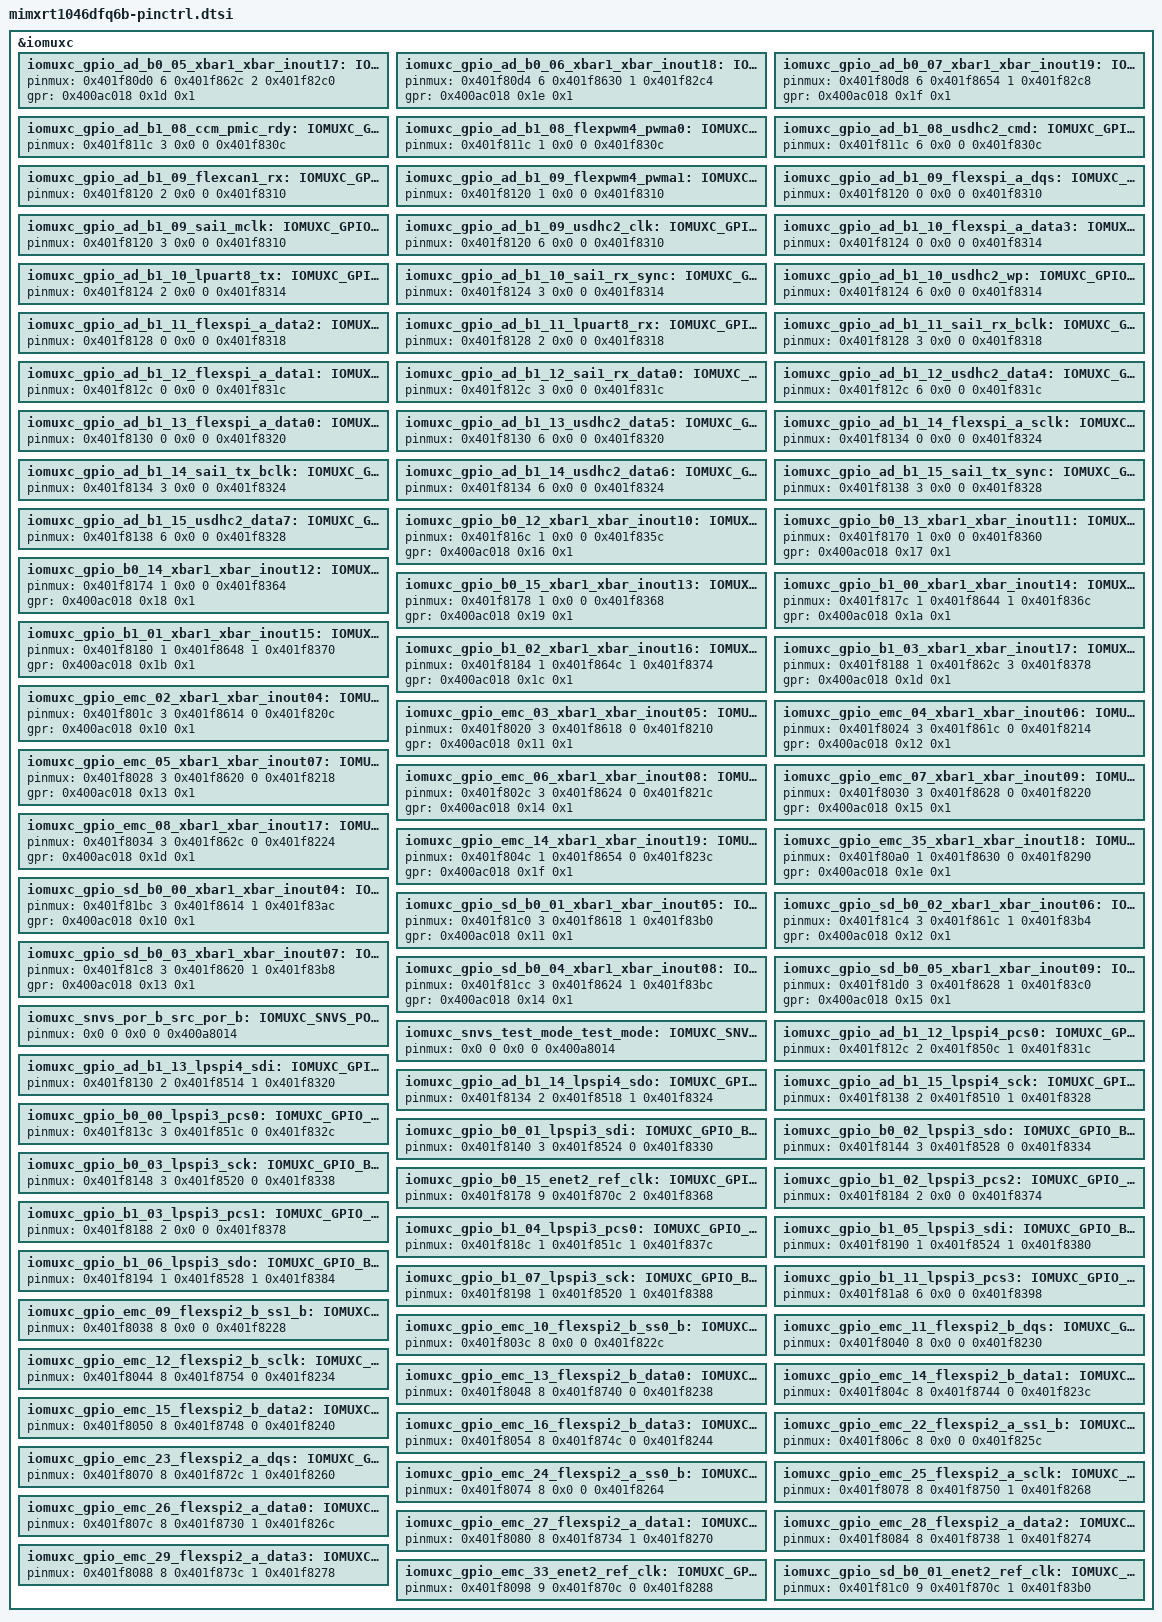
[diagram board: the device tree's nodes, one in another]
/*
 * Copyright 2026, NXP
 * SPDX-License-Identifier: Apache-2.0
 *
 * Note: File generated by gen_soc_headers.py
 * from configuration data for MIMXRT1046DFQ6B
 */

/*
 * Delta-deduplicated by dedup_pinctrl.py:
 * based on mimxrt1064dvj6a-pinctrl.dtsi with this part's differences applied
 * below (223 removed, 53 changed,
 * 34 added). Regenerate with dedup_pinctrl.py;
 * do not edit by hand.
 * target-hash: 304d2df1a5f7ddd6
 */

#include "mimxrt1064dvj6a-pinctrl.dtsi"

/delete-node/ &iomuxc_gpio_ad_b0_00_acmp1_in4;
/delete-node/ &iomuxc_gpio_ad_b0_00_flexpwm2_pwma3;
/delete-node/ &iomuxc_gpio_ad_b0_00_gpio1_io00;
/delete-node/ &iomuxc_gpio_ad_b0_00_gpio6_io00;
/delete-node/ &iomuxc_gpio_ad_b0_00_lpi2c1_scls;
/delete-node/ &iomuxc_gpio_ad_b0_00_lpspi3_sck;
/delete-node/ &iomuxc_gpio_ad_b0_00_ref_32k_out;
/delete-node/ &iomuxc_gpio_ad_b0_00_usb_otg2_id;
/delete-node/ &iomuxc_gpio_ad_b0_00_usdhc1_reset_b;
/delete-node/ &iomuxc_gpio_ad_b0_00_xbar1_xbar_in14;
/delete-node/ &iomuxc_gpio_ad_b0_00_xbar1_xbar_inout14;
/delete-node/ &iomuxc_gpio_ad_b0_01_acmp2_in4;
/delete-node/ &iomuxc_gpio_ad_b0_01_ewm_out_b;
/delete-node/ &iomuxc_gpio_ad_b0_01_flexpwm2_pwmb3;
/delete-node/ &iomuxc_gpio_ad_b0_01_gpio1_io01;
/delete-node/ &iomuxc_gpio_ad_b0_01_gpio6_io01;
/delete-node/ &iomuxc_gpio_ad_b0_01_lpi2c1_sdas;
/delete-node/ &iomuxc_gpio_ad_b0_01_lpspi3_sdo;
/delete-node/ &iomuxc_gpio_ad_b0_01_ref_24m_out;
/delete-node/ &iomuxc_gpio_ad_b0_01_usb_otg1_id;
/delete-node/ &iomuxc_gpio_ad_b0_01_xbar1_xbar_in15;
/delete-node/ &iomuxc_gpio_ad_b0_01_xbar1_xbar_inout15;
/delete-node/ &iomuxc_gpio_ad_b0_02_acmp3_in4;
/delete-node/ &iomuxc_gpio_ad_b0_02_flexcan2_tx;
/delete-node/ &iomuxc_gpio_ad_b0_02_flexpwm1_pwmx0;
/delete-node/ &iomuxc_gpio_ad_b0_02_gpio1_io02;
/delete-node/ &iomuxc_gpio_ad_b0_02_gpio6_io02;
/delete-node/ &iomuxc_gpio_ad_b0_02_lpi2c1_hreq;
/delete-node/ &iomuxc_gpio_ad_b0_02_lpspi3_sdi;
/delete-node/ &iomuxc_gpio_ad_b0_02_lpuart6_tx;
/delete-node/ &iomuxc_gpio_ad_b0_02_usb_otg1_pwr;
/delete-node/ &iomuxc_gpio_ad_b0_02_xbar1_xbar_in16;
/delete-node/ &iomuxc_gpio_ad_b0_02_xbar1_xbar_inout16;
/delete-node/ &iomuxc_gpio_ad_b0_03_acmp4_in4;
/delete-node/ &iomuxc_gpio_ad_b0_03_flexcan2_rx;
/delete-node/ &iomuxc_gpio_ad_b0_03_flexpwm1_pwmx1;
/delete-node/ &iomuxc_gpio_ad_b0_03_gpio1_io03;
/delete-node/ &iomuxc_gpio_ad_b0_03_gpio6_io03;
/delete-node/ &iomuxc_gpio_ad_b0_03_lpspi3_pcs0;
/delete-node/ &iomuxc_gpio_ad_b0_03_lpuart6_rx;
/delete-node/ &iomuxc_gpio_ad_b0_03_ref_24m_out;
/delete-node/ &iomuxc_gpio_ad_b0_03_usb_otg1_oc;
/delete-node/ &iomuxc_gpio_ad_b0_03_xbar1_xbar_in17;
/delete-node/ &iomuxc_gpio_ad_b0_03_xbar1_xbar_inout17;
/delete-node/ &iomuxc_gpio_ad_b0_04_csi_data09;
/delete-node/ &iomuxc_gpio_ad_b0_04_lpspi3_pcs1;
/delete-node/ &iomuxc_gpio_ad_b0_05_csi_data08;
/delete-node/ &iomuxc_gpio_ad_b0_05_lpspi3_pcs2;
/delete-node/ &iomuxc_gpio_ad_b0_06_csi_data07;
/delete-node/ &iomuxc_gpio_ad_b0_06_lpspi3_pcs3;
/delete-node/ &iomuxc_gpio_ad_b0_07_csi_data06;
/delete-node/ &iomuxc_gpio_ad_b0_08_csi_data05;
/delete-node/ &iomuxc_gpio_ad_b0_09_csi_data04;
/delete-node/ &iomuxc_gpio_ad_b0_10_csi_data03;
/delete-node/ &iomuxc_gpio_ad_b0_11_csi_data02;
/delete-node/ &iomuxc_gpio_ad_b0_14_acmp2_in2;
/delete-node/ &iomuxc_gpio_ad_b0_14_adc1_in3;
/delete-node/ &iomuxc_gpio_ad_b0_14_csi_vsync;
/delete-node/ &iomuxc_gpio_ad_b0_14_enet_1588_event0_out;
/delete-node/ &iomuxc_gpio_ad_b0_14_flexcan2_tx;
/delete-node/ &iomuxc_gpio_ad_b0_14_flexcan3_tx;
/delete-node/ &iomuxc_gpio_ad_b0_14_gpio1_io14;
/delete-node/ &iomuxc_gpio_ad_b0_14_gpio6_io14;
/delete-node/ &iomuxc_gpio_ad_b0_14_lpuart1_cts_b;
/delete-node/ &iomuxc_gpio_ad_b0_14_usb_otg2_oc;
/delete-node/ &iomuxc_gpio_ad_b0_14_xbar1_xbar_in24;
/delete-node/ &iomuxc_gpio_ad_b0_15_acmp3_in2;
/delete-node/ &iomuxc_gpio_ad_b0_15_adc1_in4;
/delete-node/ &iomuxc_gpio_ad_b0_15_csi_hsync;
/delete-node/ &iomuxc_gpio_ad_b0_15_enet_1588_event0_in;
/delete-node/ &iomuxc_gpio_ad_b0_15_flexcan2_rx;
/delete-node/ &iomuxc_gpio_ad_b0_15_flexcan3_rx;
/delete-node/ &iomuxc_gpio_ad_b0_15_gpio1_io15;
/delete-node/ &iomuxc_gpio_ad_b0_15_gpio6_io15;
/delete-node/ &iomuxc_gpio_ad_b0_15_lpuart1_rts_b;
/delete-node/ &iomuxc_gpio_ad_b0_15_usb_otg2_pwr;
/delete-node/ &iomuxc_gpio_ad_b0_15_wdog1_rst_b_deb;
/delete-node/ &iomuxc_gpio_ad_b0_15_xbar1_xbar_in25;
/delete-node/ &iomuxc_gpio_ad_b1_00_acmp4_in2;
/delete-node/ &iomuxc_gpio_ad_b1_00_adc1_in5;
/delete-node/ &iomuxc_gpio_ad_b1_00_adc2_in5;
/delete-node/ &iomuxc_gpio_ad_b1_00_enet2_1588_event0_out;
/delete-node/ &iomuxc_gpio_ad_b1_00_flexio3_flexio00;
/delete-node/ &iomuxc_gpio_ad_b1_00_gpio1_io16;
/delete-node/ &iomuxc_gpio_ad_b1_00_gpio6_io16;
/delete-node/ &iomuxc_gpio_ad_b1_00_kpp_row7;
/delete-node/ &iomuxc_gpio_ad_b1_00_lpi2c1_scl;
/delete-node/ &iomuxc_gpio_ad_b1_00_lpuart2_cts_b;
/delete-node/ &iomuxc_gpio_ad_b1_00_qtimer3_timer0;
/delete-node/ &iomuxc_gpio_ad_b1_00_usb_otg2_id;
/delete-node/ &iomuxc_gpio_ad_b1_00_usdhc1_wp;
/delete-node/ &iomuxc_gpio_ad_b1_00_wdog1_b;
/delete-node/ &iomuxc_gpio_ad_b1_01_acmp1_in0;
/delete-node/ &iomuxc_gpio_ad_b1_01_acmp2_in0;
/delete-node/ &iomuxc_gpio_ad_b1_01_acmp3_in0;
/delete-node/ &iomuxc_gpio_ad_b1_01_acmp4_in0;
/delete-node/ &iomuxc_gpio_ad_b1_01_adc1_in6;
/delete-node/ &iomuxc_gpio_ad_b1_01_adc2_in6;
/delete-node/ &iomuxc_gpio_ad_b1_01_ccm_pmic_rdy;
/delete-node/ &iomuxc_gpio_ad_b1_01_enet2_1588_event0_in;
/delete-node/ &iomuxc_gpio_ad_b1_01_flexio3_flexio01;
/delete-node/ &iomuxc_gpio_ad_b1_01_gpio1_io17;
/delete-node/ &iomuxc_gpio_ad_b1_01_gpio6_io17;
/delete-node/ &iomuxc_gpio_ad_b1_01_kpp_col7;
/delete-node/ &iomuxc_gpio_ad_b1_01_lpi2c1_sda;
/delete-node/ &iomuxc_gpio_ad_b1_01_lpuart2_rts_b;
/delete-node/ &iomuxc_gpio_ad_b1_01_qtimer3_timer1;
/delete-node/ &iomuxc_gpio_ad_b1_01_usb_otg1_pwr;
/delete-node/ &iomuxc_gpio_ad_b1_01_usdhc1_vselect;
/delete-node/ &iomuxc_gpio_ad_b1_02_acmp1_in3;
/delete-node/ &iomuxc_gpio_ad_b1_02_adc1_in7;
/delete-node/ &iomuxc_gpio_ad_b1_02_adc2_in7;
/delete-node/ &iomuxc_gpio_ad_b1_02_enet_1588_event2_out;
/delete-node/ &iomuxc_gpio_ad_b1_02_flexio3_flexio02;
/delete-node/ &iomuxc_gpio_ad_b1_02_gpio1_io18;
/delete-node/ &iomuxc_gpio_ad_b1_02_gpio6_io18;
/delete-node/ &iomuxc_gpio_ad_b1_02_gpt2_clk;
/delete-node/ &iomuxc_gpio_ad_b1_02_kpp_row6;
/delete-node/ &iomuxc_gpio_ad_b1_02_lpuart2_tx;
/delete-node/ &iomuxc_gpio_ad_b1_02_qtimer3_timer2;
/delete-node/ &iomuxc_gpio_ad_b1_02_spdif_out;
/delete-node/ &iomuxc_gpio_ad_b1_02_usb_otg1_id;
/delete-node/ &iomuxc_gpio_ad_b1_02_usdhc1_cd_b;
/delete-node/ &iomuxc_gpio_ad_b1_03_kpp_col6;
/delete-node/ &iomuxc_gpio_ad_b1_04_csi_pixclk;
/delete-node/ &iomuxc_gpio_ad_b1_04_kpp_row5;
/delete-node/ &iomuxc_gpio_ad_b1_05_csi_mclk;
/delete-node/ &iomuxc_gpio_ad_b1_05_kpp_col5;
/delete-node/ &iomuxc_gpio_ad_b1_06_csi_vsync;
/delete-node/ &iomuxc_gpio_ad_b1_06_kpp_row4;
/delete-node/ &iomuxc_gpio_ad_b1_07_csi_hsync;
/delete-node/ &iomuxc_gpio_ad_b1_07_kpp_col4;
/delete-node/ &iomuxc_gpio_ad_b1_08_csi_data09;
/delete-node/ &iomuxc_gpio_ad_b1_08_kpp_row3;
/delete-node/ &iomuxc_gpio_ad_b1_09_csi_data08;
/delete-node/ &iomuxc_gpio_ad_b1_09_kpp_col3;
/delete-node/ &iomuxc_gpio_ad_b1_10_csi_data07;
/delete-node/ &iomuxc_gpio_ad_b1_10_kpp_row2;
/delete-node/ &iomuxc_gpio_ad_b1_11_csi_data06;
/delete-node/ &iomuxc_gpio_ad_b1_11_kpp_col2;
/delete-node/ &iomuxc_gpio_ad_b1_12_csi_data05;
/delete-node/ &iomuxc_gpio_ad_b1_12_kpp_row1;
/delete-node/ &iomuxc_gpio_ad_b1_12_lpspi3_pcs0;
/delete-node/ &iomuxc_gpio_ad_b1_13_csi_data04;
/delete-node/ &iomuxc_gpio_ad_b1_13_kpp_col1;
/delete-node/ &iomuxc_gpio_ad_b1_13_lpspi3_sdi;
/delete-node/ &iomuxc_gpio_ad_b1_14_csi_data03;
/delete-node/ &iomuxc_gpio_ad_b1_14_kpp_row0;
/delete-node/ &iomuxc_gpio_ad_b1_14_lpspi3_sdo;
/delete-node/ &iomuxc_gpio_ad_b1_15_csi_data02;
/delete-node/ &iomuxc_gpio_ad_b1_15_kpp_col0;
/delete-node/ &iomuxc_gpio_ad_b1_15_lpspi3_sck;
/delete-node/ &iomuxc_gpio_b0_00_lcdif_clk;
/delete-node/ &iomuxc_gpio_b0_00_lpspi4_pcs0;
/delete-node/ &iomuxc_gpio_b0_01_lcdif_enable;
/delete-node/ &iomuxc_gpio_b0_01_lpspi4_sdi;
/delete-node/ &iomuxc_gpio_b0_02_lcdif_hsync;
/delete-node/ &iomuxc_gpio_b0_02_lpspi4_sdo;
/delete-node/ &iomuxc_gpio_b0_03_lcdif_vsync;
/delete-node/ &iomuxc_gpio_b0_03_lpspi4_sck;
/delete-node/ &iomuxc_gpio_b0_04_lcdif_data00;
/delete-node/ &iomuxc_gpio_b0_05_lcdif_data01;
/delete-node/ &iomuxc_gpio_b0_06_lcdif_data02;
/delete-node/ &iomuxc_gpio_b0_07_lcdif_data03;
/delete-node/ &iomuxc_gpio_b0_08_lcdif_data04;
/delete-node/ &iomuxc_gpio_b0_09_lcdif_data05;
/delete-node/ &iomuxc_gpio_b0_10_lcdif_data06;
/delete-node/ &iomuxc_gpio_b0_11_lcdif_data07;
/delete-node/ &iomuxc_gpio_b0_12_lcdif_data08;
/delete-node/ &iomuxc_gpio_b0_13_lcdif_data09;
/delete-node/ &iomuxc_gpio_b0_14_arm_txev;
/delete-node/ &iomuxc_gpio_b0_14_lcdif_data10;
/delete-node/ &iomuxc_gpio_b0_15_arm_rxev;
/delete-node/ &iomuxc_gpio_b0_15_enet2_ref_clk2;
/delete-node/ &iomuxc_gpio_b0_15_lcdif_data11;
/delete-node/ &iomuxc_gpio_b1_00_lcdif_data12;
/delete-node/ &iomuxc_gpio_b1_01_lcdif_data13;
/delete-node/ &iomuxc_gpio_b1_02_lcdif_data14;
/delete-node/ &iomuxc_gpio_b1_02_lpspi4_pcs2;
/delete-node/ &iomuxc_gpio_b1_03_lcdif_data15;
/delete-node/ &iomuxc_gpio_b1_03_lpspi4_pcs1;
/delete-node/ &iomuxc_gpio_b1_04_csi_data15;
/delete-node/ &iomuxc_gpio_b1_04_lcdif_data16;
/delete-node/ &iomuxc_gpio_b1_04_lpspi4_pcs0;
/delete-node/ &iomuxc_gpio_b1_05_csi_data14;
/delete-node/ &iomuxc_gpio_b1_05_lcdif_data17;
/delete-node/ &iomuxc_gpio_b1_05_lpspi4_sdi;
/delete-node/ &iomuxc_gpio_b1_06_csi_data13;
/delete-node/ &iomuxc_gpio_b1_06_lcdif_data18;
/delete-node/ &iomuxc_gpio_b1_06_lpspi4_sdo;
/delete-node/ &iomuxc_gpio_b1_07_csi_data12;
/delete-node/ &iomuxc_gpio_b1_07_lcdif_data19;
/delete-node/ &iomuxc_gpio_b1_07_lpspi4_sck;
/delete-node/ &iomuxc_gpio_b1_08_csi_data11;
/delete-node/ &iomuxc_gpio_b1_08_lcdif_data20;
/delete-node/ &iomuxc_gpio_b1_09_csi_data10;
/delete-node/ &iomuxc_gpio_b1_09_lcdif_data21;
/delete-node/ &iomuxc_gpio_b1_10_csi_data00;
/delete-node/ &iomuxc_gpio_b1_10_lcdif_data22;
/delete-node/ &iomuxc_gpio_b1_11_csi_data01;
/delete-node/ &iomuxc_gpio_b1_11_lcdif_data23;
/delete-node/ &iomuxc_gpio_b1_11_lpspi4_pcs3;
/delete-node/ &iomuxc_gpio_b1_12_csi_pixclk;
/delete-node/ &iomuxc_gpio_b1_13_csi_vsync;
/delete-node/ &iomuxc_gpio_b1_14_csi_hsync;
/delete-node/ &iomuxc_gpio_b1_15_csi_mclk;
/delete-node/ &iomuxc_gpio_emc_30_csi_data23;
/delete-node/ &iomuxc_gpio_emc_31_csi_data22;
/delete-node/ &iomuxc_gpio_emc_32_csi_data21;
/delete-node/ &iomuxc_gpio_emc_33_csi_data20;
/delete-node/ &iomuxc_gpio_emc_33_enet2_ref_clk2;
/delete-node/ &iomuxc_gpio_emc_34_csi_data19;
/delete-node/ &iomuxc_gpio_emc_35_csi_data18;
/delete-node/ &iomuxc_gpio_emc_36_csi_data17;
/delete-node/ &iomuxc_gpio_emc_37_csi_data16;
/delete-node/ &iomuxc_gpio_emc_38_csi_field;
/delete-node/ &iomuxc_gpio_emc_40_usb_otg2_oc;
/delete-node/ &iomuxc_gpio_emc_41_usb_otg2_pwr;
/delete-node/ &iomuxc_gpio_sd_b0_01_enet2_ref_clk2;
/delete-node/ &iomuxc_snvs_pmic_stby_req_ccm_pmic_vstby_req;
/delete-node/ &iomuxc_snvs_pmic_stby_req_gpio5_io02;
/delete-node/ &iomuxc_snvs_wakeup_arm_nmi;
/delete-node/ &iomuxc_snvs_wakeup_gpio5_io00;
/delete-node/ &iomuxc_gpio_ad_b0_05_xbar1_xbar_inout17;
/delete-node/ &iomuxc_gpio_ad_b0_06_xbar1_xbar_inout18;
/delete-node/ &iomuxc_gpio_ad_b0_07_xbar1_xbar_inout19;
/delete-node/ &iomuxc_gpio_ad_b1_08_ccm_pmic_rdy;
/delete-node/ &iomuxc_gpio_ad_b1_08_flexpwm4_pwma0;
/delete-node/ &iomuxc_gpio_ad_b1_08_usdhc2_cmd;
/delete-node/ &iomuxc_gpio_ad_b1_09_flexcan1_rx;
/delete-node/ &iomuxc_gpio_ad_b1_09_flexpwm4_pwma1;
/delete-node/ &iomuxc_gpio_ad_b1_09_flexspi_a_dqs;
/delete-node/ &iomuxc_gpio_ad_b1_09_sai1_mclk;
/delete-node/ &iomuxc_gpio_ad_b1_09_usdhc2_clk;
/delete-node/ &iomuxc_gpio_ad_b1_10_flexspi_a_data3;
/delete-node/ &iomuxc_gpio_ad_b1_10_lpuart8_tx;
/delete-node/ &iomuxc_gpio_ad_b1_10_sai1_rx_sync;
/delete-node/ &iomuxc_gpio_ad_b1_10_usdhc2_wp;
/delete-node/ &iomuxc_gpio_ad_b1_11_flexspi_a_data2;
/delete-node/ &iomuxc_gpio_ad_b1_11_lpuart8_rx;
/delete-node/ &iomuxc_gpio_ad_b1_11_sai1_rx_bclk;
/delete-node/ &iomuxc_gpio_ad_b1_12_flexspi_a_data1;
/delete-node/ &iomuxc_gpio_ad_b1_12_sai1_rx_data0;
/delete-node/ &iomuxc_gpio_ad_b1_12_usdhc2_data4;
/delete-node/ &iomuxc_gpio_ad_b1_13_flexspi_a_data0;
/delete-node/ &iomuxc_gpio_ad_b1_13_usdhc2_data5;
/delete-node/ &iomuxc_gpio_ad_b1_14_flexspi_a_sclk;
/delete-node/ &iomuxc_gpio_ad_b1_14_sai1_tx_bclk;
/delete-node/ &iomuxc_gpio_ad_b1_14_usdhc2_data6;
/delete-node/ &iomuxc_gpio_ad_b1_15_sai1_tx_sync;
/delete-node/ &iomuxc_gpio_ad_b1_15_usdhc2_data7;
/delete-node/ &iomuxc_gpio_b0_12_xbar1_xbar_inout10;
/delete-node/ &iomuxc_gpio_b0_13_xbar1_xbar_inout11;
/delete-node/ &iomuxc_gpio_b0_14_xbar1_xbar_inout12;
/delete-node/ &iomuxc_gpio_b0_15_xbar1_xbar_inout13;
/delete-node/ &iomuxc_gpio_b1_00_xbar1_xbar_inout14;
/delete-node/ &iomuxc_gpio_b1_01_xbar1_xbar_inout15;
/delete-node/ &iomuxc_gpio_b1_02_xbar1_xbar_inout16;
/delete-node/ &iomuxc_gpio_b1_03_xbar1_xbar_inout17;
/delete-node/ &iomuxc_gpio_emc_02_xbar1_xbar_inout04;
/delete-node/ &iomuxc_gpio_emc_03_xbar1_xbar_inout05;
/delete-node/ &iomuxc_gpio_emc_04_xbar1_xbar_inout06;
/delete-node/ &iomuxc_gpio_emc_05_xbar1_xbar_inout07;
/delete-node/ &iomuxc_gpio_emc_06_xbar1_xbar_inout08;
/delete-node/ &iomuxc_gpio_emc_07_xbar1_xbar_inout09;
/delete-node/ &iomuxc_gpio_emc_08_xbar1_xbar_inout17;
/delete-node/ &iomuxc_gpio_emc_14_xbar1_xbar_inout19;
/delete-node/ &iomuxc_gpio_emc_35_xbar1_xbar_inout18;
/delete-node/ &iomuxc_gpio_sd_b0_00_xbar1_xbar_inout04;
/delete-node/ &iomuxc_gpio_sd_b0_01_xbar1_xbar_inout05;
/delete-node/ &iomuxc_gpio_sd_b0_02_xbar1_xbar_inout06;
/delete-node/ &iomuxc_gpio_sd_b0_03_xbar1_xbar_inout07;
/delete-node/ &iomuxc_gpio_sd_b0_04_xbar1_xbar_inout08;
/delete-node/ &iomuxc_gpio_sd_b0_05_xbar1_xbar_inout09;
/delete-node/ &iomuxc_snvs_por_b_src_por_b;
/delete-node/ &iomuxc_snvs_test_mode_test_mode;

&iomuxc {
	/omit-if-no-ref/ iomuxc_gpio_ad_b0_05_xbar1_xbar_inout17: IOMUXC_GPIO_AD_B0_05_XBAR1_XBAR_INOUT17 {
		pinmux = <0x401f80d0 6 0x401f862c 2 0x401f82c0>;
		gpr = <0x400ac018 0x1d 0x1>;
	};
	/omit-if-no-ref/ iomuxc_gpio_ad_b0_06_xbar1_xbar_inout18: IOMUXC_GPIO_AD_B0_06_XBAR1_XBAR_INOUT18 {
		pinmux = <0x401f80d4 6 0x401f8630 1 0x401f82c4>;
		gpr = <0x400ac018 0x1e 0x1>;
	};
	/omit-if-no-ref/ iomuxc_gpio_ad_b0_07_xbar1_xbar_inout19: IOMUXC_GPIO_AD_B0_07_XBAR1_XBAR_INOUT19 {
		pinmux = <0x401f80d8 6 0x401f8654 1 0x401f82c8>;
		gpr = <0x400ac018 0x1f 0x1>;
	};
	/omit-if-no-ref/ iomuxc_gpio_ad_b1_08_ccm_pmic_rdy: IOMUXC_GPIO_AD_B1_08_CCM_PMIC_RDY {
		pinmux = <0x401f811c 3 0x0 0 0x401f830c>;
	};
	/omit-if-no-ref/ iomuxc_gpio_ad_b1_08_flexpwm4_pwma0: IOMUXC_GPIO_AD_B1_08_FLEXPWM4_PWMA0 {
		pinmux = <0x401f811c 1 0x0 0 0x401f830c>;
	};
	/omit-if-no-ref/ iomuxc_gpio_ad_b1_08_usdhc2_cmd: IOMUXC_GPIO_AD_B1_08_USDHC2_CMD {
		pinmux = <0x401f811c 6 0x0 0 0x401f830c>;
	};
	/omit-if-no-ref/ iomuxc_gpio_ad_b1_09_flexcan1_rx: IOMUXC_GPIO_AD_B1_09_FLEXCAN1_RX {
		pinmux = <0x401f8120 2 0x0 0 0x401f8310>;
	};
	/omit-if-no-ref/ iomuxc_gpio_ad_b1_09_flexpwm4_pwma1: IOMUXC_GPIO_AD_B1_09_FLEXPWM4_PWMA1 {
		pinmux = <0x401f8120 1 0x0 0 0x401f8310>;
	};
	/omit-if-no-ref/ iomuxc_gpio_ad_b1_09_flexspi_a_dqs: IOMUXC_GPIO_AD_B1_09_FLEXSPI_A_DQS {
		pinmux = <0x401f8120 0 0x0 0 0x401f8310>;
	};
	/omit-if-no-ref/ iomuxc_gpio_ad_b1_09_sai1_mclk: IOMUXC_GPIO_AD_B1_09_SAI1_MCLK {
		pinmux = <0x401f8120 3 0x0 0 0x401f8310>;
	};
	/omit-if-no-ref/ iomuxc_gpio_ad_b1_09_usdhc2_clk: IOMUXC_GPIO_AD_B1_09_USDHC2_CLK {
		pinmux = <0x401f8120 6 0x0 0 0x401f8310>;
	};
	/omit-if-no-ref/ iomuxc_gpio_ad_b1_10_flexspi_a_data3: IOMUXC_GPIO_AD_B1_10_FLEXSPI_A_DATA3 {
		pinmux = <0x401f8124 0 0x0 0 0x401f8314>;
	};
	/omit-if-no-ref/ iomuxc_gpio_ad_b1_10_lpuart8_tx: IOMUXC_GPIO_AD_B1_10_LPUART8_TX {
		pinmux = <0x401f8124 2 0x0 0 0x401f8314>;
	};
	/omit-if-no-ref/ iomuxc_gpio_ad_b1_10_sai1_rx_sync: IOMUXC_GPIO_AD_B1_10_SAI1_RX_SYNC {
		pinmux = <0x401f8124 3 0x0 0 0x401f8314>;
	};
	/omit-if-no-ref/ iomuxc_gpio_ad_b1_10_usdhc2_wp: IOMUXC_GPIO_AD_B1_10_USDHC2_WP {
		pinmux = <0x401f8124 6 0x0 0 0x401f8314>;
	};
	/omit-if-no-ref/ iomuxc_gpio_ad_b1_11_flexspi_a_data2: IOMUXC_GPIO_AD_B1_11_FLEXSPI_A_DATA2 {
		pinmux = <0x401f8128 0 0x0 0 0x401f8318>;
	};
	/omit-if-no-ref/ iomuxc_gpio_ad_b1_11_lpuart8_rx: IOMUXC_GPIO_AD_B1_11_LPUART8_RX {
		pinmux = <0x401f8128 2 0x0 0 0x401f8318>;
	};
	/omit-if-no-ref/ iomuxc_gpio_ad_b1_11_sai1_rx_bclk: IOMUXC_GPIO_AD_B1_11_SAI1_RX_BCLK {
		pinmux = <0x401f8128 3 0x0 0 0x401f8318>;
	};
	/omit-if-no-ref/ iomuxc_gpio_ad_b1_12_flexspi_a_data1: IOMUXC_GPIO_AD_B1_12_FLEXSPI_A_DATA1 {
		pinmux = <0x401f812c 0 0x0 0 0x401f831c>;
	};
	/omit-if-no-ref/ iomuxc_gpio_ad_b1_12_sai1_rx_data0: IOMUXC_GPIO_AD_B1_12_SAI1_RX_DATA0 {
		pinmux = <0x401f812c 3 0x0 0 0x401f831c>;
	};
	/omit-if-no-ref/ iomuxc_gpio_ad_b1_12_usdhc2_data4: IOMUXC_GPIO_AD_B1_12_USDHC2_DATA4 {
		pinmux = <0x401f812c 6 0x0 0 0x401f831c>;
	};
	/omit-if-no-ref/ iomuxc_gpio_ad_b1_13_flexspi_a_data0: IOMUXC_GPIO_AD_B1_13_FLEXSPI_A_DATA0 {
		pinmux = <0x401f8130 0 0x0 0 0x401f8320>;
	};
	/omit-if-no-ref/ iomuxc_gpio_ad_b1_13_usdhc2_data5: IOMUXC_GPIO_AD_B1_13_USDHC2_DATA5 {
		pinmux = <0x401f8130 6 0x0 0 0x401f8320>;
	};
	/omit-if-no-ref/ iomuxc_gpio_ad_b1_14_flexspi_a_sclk: IOMUXC_GPIO_AD_B1_14_FLEXSPI_A_SCLK {
		pinmux = <0x401f8134 0 0x0 0 0x401f8324>;
	};
	/omit-if-no-ref/ iomuxc_gpio_ad_b1_14_sai1_tx_bclk: IOMUXC_GPIO_AD_B1_14_SAI1_TX_BCLK {
		pinmux = <0x401f8134 3 0x0 0 0x401f8324>;
	};
	/omit-if-no-ref/ iomuxc_gpio_ad_b1_14_usdhc2_data6: IOMUXC_GPIO_AD_B1_14_USDHC2_DATA6 {
		pinmux = <0x401f8134 6 0x0 0 0x401f8324>;
	};
	/omit-if-no-ref/ iomuxc_gpio_ad_b1_15_sai1_tx_sync: IOMUXC_GPIO_AD_B1_15_SAI1_TX_SYNC {
		pinmux = <0x401f8138 3 0x0 0 0x401f8328>;
	};
	/omit-if-no-ref/ iomuxc_gpio_ad_b1_15_usdhc2_data7: IOMUXC_GPIO_AD_B1_15_USDHC2_DATA7 {
		pinmux = <0x401f8138 6 0x0 0 0x401f8328>;
	};
	/omit-if-no-ref/ iomuxc_gpio_b0_12_xbar1_xbar_inout10: IOMUXC_GPIO_B0_12_XBAR1_XBAR_INOUT10 {
		pinmux = <0x401f816c 1 0x0 0 0x401f835c>;
		gpr = <0x400ac018 0x16 0x1>;
	};
	/omit-if-no-ref/ iomuxc_gpio_b0_13_xbar1_xbar_inout11: IOMUXC_GPIO_B0_13_XBAR1_XBAR_INOUT11 {
		pinmux = <0x401f8170 1 0x0 0 0x401f8360>;
		gpr = <0x400ac018 0x17 0x1>;
	};
	/omit-if-no-ref/ iomuxc_gpio_b0_14_xbar1_xbar_inout12: IOMUXC_GPIO_B0_14_XBAR1_XBAR_INOUT12 {
		pinmux = <0x401f8174 1 0x0 0 0x401f8364>;
		gpr = <0x400ac018 0x18 0x1>;
	};
	/omit-if-no-ref/ iomuxc_gpio_b0_15_xbar1_xbar_inout13: IOMUXC_GPIO_B0_15_XBAR1_XBAR_INOUT13 {
		pinmux = <0x401f8178 1 0x0 0 0x401f8368>;
		gpr = <0x400ac018 0x19 0x1>;
	};
	/omit-if-no-ref/ iomuxc_gpio_b1_00_xbar1_xbar_inout14: IOMUXC_GPIO_B1_00_XBAR1_XBAR_INOUT14 {
		pinmux = <0x401f817c 1 0x401f8644 1 0x401f836c>;
		gpr = <0x400ac018 0x1a 0x1>;
	};
	/omit-if-no-ref/ iomuxc_gpio_b1_01_xbar1_xbar_inout15: IOMUXC_GPIO_B1_01_XBAR1_XBAR_INOUT15 {
		pinmux = <0x401f8180 1 0x401f8648 1 0x401f8370>;
		gpr = <0x400ac018 0x1b 0x1>;
	};
	/omit-if-no-ref/ iomuxc_gpio_b1_02_xbar1_xbar_inout16: IOMUXC_GPIO_B1_02_XBAR1_XBAR_INOUT16 {
		pinmux = <0x401f8184 1 0x401f864c 1 0x401f8374>;
		gpr = <0x400ac018 0x1c 0x1>;
	};
	/omit-if-no-ref/ iomuxc_gpio_b1_03_xbar1_xbar_inout17: IOMUXC_GPIO_B1_03_XBAR1_XBAR_INOUT17 {
		pinmux = <0x401f8188 1 0x401f862c 3 0x401f8378>;
		gpr = <0x400ac018 0x1d 0x1>;
	};
	/omit-if-no-ref/ iomuxc_gpio_emc_02_xbar1_xbar_inout04: IOMUXC_GPIO_EMC_02_XBAR1_XBAR_INOUT04 {
		pinmux = <0x401f801c 3 0x401f8614 0 0x401f820c>;
		gpr = <0x400ac018 0x10 0x1>;
	};
	/omit-if-no-ref/ iomuxc_gpio_emc_03_xbar1_xbar_inout05: IOMUXC_GPIO_EMC_03_XBAR1_XBAR_INOUT05 {
		pinmux = <0x401f8020 3 0x401f8618 0 0x401f8210>;
		gpr = <0x400ac018 0x11 0x1>;
	};
	/omit-if-no-ref/ iomuxc_gpio_emc_04_xbar1_xbar_inout06: IOMUXC_GPIO_EMC_04_XBAR1_XBAR_INOUT06 {
		pinmux = <0x401f8024 3 0x401f861c 0 0x401f8214>;
		gpr = <0x400ac018 0x12 0x1>;
	};
	/omit-if-no-ref/ iomuxc_gpio_emc_05_xbar1_xbar_inout07: IOMUXC_GPIO_EMC_05_XBAR1_XBAR_INOUT07 {
		pinmux = <0x401f8028 3 0x401f8620 0 0x401f8218>;
		gpr = <0x400ac018 0x13 0x1>;
	};
	/omit-if-no-ref/ iomuxc_gpio_emc_06_xbar1_xbar_inout08: IOMUXC_GPIO_EMC_06_XBAR1_XBAR_INOUT08 {
		pinmux = <0x401f802c 3 0x401f8624 0 0x401f821c>;
		gpr = <0x400ac018 0x14 0x1>;
	};
	/omit-if-no-ref/ iomuxc_gpio_emc_07_xbar1_xbar_inout09: IOMUXC_GPIO_EMC_07_XBAR1_XBAR_INOUT09 {
		pinmux = <0x401f8030 3 0x401f8628 0 0x401f8220>;
		gpr = <0x400ac018 0x15 0x1>;
	};
	/omit-if-no-ref/ iomuxc_gpio_emc_08_xbar1_xbar_inout17: IOMUXC_GPIO_EMC_08_XBAR1_XBAR_INOUT17 {
		pinmux = <0x401f8034 3 0x401f862c 0 0x401f8224>;
		gpr = <0x400ac018 0x1d 0x1>;
	};
	/omit-if-no-ref/ iomuxc_gpio_emc_14_xbar1_xbar_inout19: IOMUXC_GPIO_EMC_14_XBAR1_XBAR_INOUT19 {
		pinmux = <0x401f804c 1 0x401f8654 0 0x401f823c>;
		gpr = <0x400ac018 0x1f 0x1>;
	};
	/omit-if-no-ref/ iomuxc_gpio_emc_35_xbar1_xbar_inout18: IOMUXC_GPIO_EMC_35_XBAR1_XBAR_INOUT18 {
		pinmux = <0x401f80a0 1 0x401f8630 0 0x401f8290>;
		gpr = <0x400ac018 0x1e 0x1>;
	};
	/omit-if-no-ref/ iomuxc_gpio_sd_b0_00_xbar1_xbar_inout04: IOMUXC_GPIO_SD_B0_00_XBAR1_XBAR_INOUT04 {
		pinmux = <0x401f81bc 3 0x401f8614 1 0x401f83ac>;
		gpr = <0x400ac018 0x10 0x1>;
	};
	/omit-if-no-ref/ iomuxc_gpio_sd_b0_01_xbar1_xbar_inout05: IOMUXC_GPIO_SD_B0_01_XBAR1_XBAR_INOUT05 {
		pinmux = <0x401f81c0 3 0x401f8618 1 0x401f83b0>;
		gpr = <0x400ac018 0x11 0x1>;
	};
	/omit-if-no-ref/ iomuxc_gpio_sd_b0_02_xbar1_xbar_inout06: IOMUXC_GPIO_SD_B0_02_XBAR1_XBAR_INOUT06 {
		pinmux = <0x401f81c4 3 0x401f861c 1 0x401f83b4>;
		gpr = <0x400ac018 0x12 0x1>;
	};
	/omit-if-no-ref/ iomuxc_gpio_sd_b0_03_xbar1_xbar_inout07: IOMUXC_GPIO_SD_B0_03_XBAR1_XBAR_INOUT07 {
		pinmux = <0x401f81c8 3 0x401f8620 1 0x401f83b8>;
		gpr = <0x400ac018 0x13 0x1>;
	};
	/omit-if-no-ref/ iomuxc_gpio_sd_b0_04_xbar1_xbar_inout08: IOMUXC_GPIO_SD_B0_04_XBAR1_XBAR_INOUT08 {
		pinmux = <0x401f81cc 3 0x401f8624 1 0x401f83bc>;
		gpr = <0x400ac018 0x14 0x1>;
	};
	/omit-if-no-ref/ iomuxc_gpio_sd_b0_05_xbar1_xbar_inout09: IOMUXC_GPIO_SD_B0_05_XBAR1_XBAR_INOUT09 {
		pinmux = <0x401f81d0 3 0x401f8628 1 0x401f83c0>;
		gpr = <0x400ac018 0x15 0x1>;
	};
	/omit-if-no-ref/ iomuxc_snvs_por_b_src_por_b: IOMUXC_SNVS_POR_B_SRC_POR_B {
		pinmux = <0x0 0 0x0 0 0x400a8014>;
	};
	/omit-if-no-ref/ iomuxc_snvs_test_mode_test_mode: IOMUXC_SNVS_TEST_MODE_TEST_MODE {
		pinmux = <0x0 0 0x0 0 0x400a8014>;
	};
	/omit-if-no-ref/ iomuxc_gpio_ad_b1_12_lpspi4_pcs0: IOMUXC_GPIO_AD_B1_12_LPSPI4_PCS0 {
		pinmux = <0x401f812c 2 0x401f850c 1 0x401f831c>;
	};
	/omit-if-no-ref/ iomuxc_gpio_ad_b1_13_lpspi4_sdi: IOMUXC_GPIO_AD_B1_13_LPSPI4_SDI {
		pinmux = <0x401f8130 2 0x401f8514 1 0x401f8320>;
	};
	/omit-if-no-ref/ iomuxc_gpio_ad_b1_14_lpspi4_sdo: IOMUXC_GPIO_AD_B1_14_LPSPI4_SDO {
		pinmux = <0x401f8134 2 0x401f8518 1 0x401f8324>;
	};
	/omit-if-no-ref/ iomuxc_gpio_ad_b1_15_lpspi4_sck: IOMUXC_GPIO_AD_B1_15_LPSPI4_SCK {
		pinmux = <0x401f8138 2 0x401f8510 1 0x401f8328>;
	};
	/omit-if-no-ref/ iomuxc_gpio_b0_00_lpspi3_pcs0: IOMUXC_GPIO_B0_00_LPSPI3_PCS0 {
		pinmux = <0x401f813c 3 0x401f851c 0 0x401f832c>;
	};
	/omit-if-no-ref/ iomuxc_gpio_b0_01_lpspi3_sdi: IOMUXC_GPIO_B0_01_LPSPI3_SDI {
		pinmux = <0x401f8140 3 0x401f8524 0 0x401f8330>;
	};
	/omit-if-no-ref/ iomuxc_gpio_b0_02_lpspi3_sdo: IOMUXC_GPIO_B0_02_LPSPI3_SDO {
		pinmux = <0x401f8144 3 0x401f8528 0 0x401f8334>;
	};
	/omit-if-no-ref/ iomuxc_gpio_b0_03_lpspi3_sck: IOMUXC_GPIO_B0_03_LPSPI3_SCK {
		pinmux = <0x401f8148 3 0x401f8520 0 0x401f8338>;
	};
	/omit-if-no-ref/ iomuxc_gpio_b0_15_enet2_ref_clk: IOMUXC_GPIO_B0_15_ENET2_REF_CLK {
		pinmux = <0x401f8178 9 0x401f870c 2 0x401f8368>;
	};
	/omit-if-no-ref/ iomuxc_gpio_b1_02_lpspi3_pcs2: IOMUXC_GPIO_B1_02_LPSPI3_PCS2 {
		pinmux = <0x401f8184 2 0x0 0 0x401f8374>;
	};
	/omit-if-no-ref/ iomuxc_gpio_b1_03_lpspi3_pcs1: IOMUXC_GPIO_B1_03_LPSPI3_PCS1 {
		pinmux = <0x401f8188 2 0x0 0 0x401f8378>;
	};
	/omit-if-no-ref/ iomuxc_gpio_b1_04_lpspi3_pcs0: IOMUXC_GPIO_B1_04_LPSPI3_PCS0 {
		pinmux = <0x401f818c 1 0x401f851c 1 0x401f837c>;
	};
	/omit-if-no-ref/ iomuxc_gpio_b1_05_lpspi3_sdi: IOMUXC_GPIO_B1_05_LPSPI3_SDI {
		pinmux = <0x401f8190 1 0x401f8524 1 0x401f8380>;
	};
	/omit-if-no-ref/ iomuxc_gpio_b1_06_lpspi3_sdo: IOMUXC_GPIO_B1_06_LPSPI3_SDO {
		pinmux = <0x401f8194 1 0x401f8528 1 0x401f8384>;
	};
	/omit-if-no-ref/ iomuxc_gpio_b1_07_lpspi3_sck: IOMUXC_GPIO_B1_07_LPSPI3_SCK {
		pinmux = <0x401f8198 1 0x401f8520 1 0x401f8388>;
	};
	/omit-if-no-ref/ iomuxc_gpio_b1_11_lpspi3_pcs3: IOMUXC_GPIO_B1_11_LPSPI3_PCS3 {
		pinmux = <0x401f81a8 6 0x0 0 0x401f8398>;
	};
	/omit-if-no-ref/ iomuxc_gpio_emc_09_flexspi2_b_ss1_b: IOMUXC_GPIO_EMC_09_FLEXSPI2_B_SS1_B {
		pinmux = <0x401f8038 8 0x0 0 0x401f8228>;
	};
	/omit-if-no-ref/ iomuxc_gpio_emc_10_flexspi2_b_ss0_b: IOMUXC_GPIO_EMC_10_FLEXSPI2_B_SS0_B {
		pinmux = <0x401f803c 8 0x0 0 0x401f822c>;
	};
	/omit-if-no-ref/ iomuxc_gpio_emc_11_flexspi2_b_dqs: IOMUXC_GPIO_EMC_11_FLEXSPI2_B_DQS {
		pinmux = <0x401f8040 8 0x0 0 0x401f8230>;
	};
	/omit-if-no-ref/ iomuxc_gpio_emc_12_flexspi2_b_sclk: IOMUXC_GPIO_EMC_12_FLEXSPI2_B_SCLK {
		pinmux = <0x401f8044 8 0x401f8754 0 0x401f8234>;
	};
	/omit-if-no-ref/ iomuxc_gpio_emc_13_flexspi2_b_data0: IOMUXC_GPIO_EMC_13_FLEXSPI2_B_DATA0 {
		pinmux = <0x401f8048 8 0x401f8740 0 0x401f8238>;
	};
	/omit-if-no-ref/ iomuxc_gpio_emc_14_flexspi2_b_data1: IOMUXC_GPIO_EMC_14_FLEXSPI2_B_DATA1 {
		pinmux = <0x401f804c 8 0x401f8744 0 0x401f823c>;
	};
	/omit-if-no-ref/ iomuxc_gpio_emc_15_flexspi2_b_data2: IOMUXC_GPIO_EMC_15_FLEXSPI2_B_DATA2 {
		pinmux = <0x401f8050 8 0x401f8748 0 0x401f8240>;
	};
	/omit-if-no-ref/ iomuxc_gpio_emc_16_flexspi2_b_data3: IOMUXC_GPIO_EMC_16_FLEXSPI2_B_DATA3 {
		pinmux = <0x401f8054 8 0x401f874c 0 0x401f8244>;
	};
	/omit-if-no-ref/ iomuxc_gpio_emc_22_flexspi2_a_ss1_b: IOMUXC_GPIO_EMC_22_FLEXSPI2_A_SS1_B {
		pinmux = <0x401f806c 8 0x0 0 0x401f825c>;
	};
	/omit-if-no-ref/ iomuxc_gpio_emc_23_flexspi2_a_dqs: IOMUXC_GPIO_EMC_23_FLEXSPI2_A_DQS {
		pinmux = <0x401f8070 8 0x401f872c 1 0x401f8260>;
	};
	/omit-if-no-ref/ iomuxc_gpio_emc_24_flexspi2_a_ss0_b: IOMUXC_GPIO_EMC_24_FLEXSPI2_A_SS0_B {
		pinmux = <0x401f8074 8 0x0 0 0x401f8264>;
	};
	/omit-if-no-ref/ iomuxc_gpio_emc_25_flexspi2_a_sclk: IOMUXC_GPIO_EMC_25_FLEXSPI2_A_SCLK {
		pinmux = <0x401f8078 8 0x401f8750 1 0x401f8268>;
	};
	/omit-if-no-ref/ iomuxc_gpio_emc_26_flexspi2_a_data0: IOMUXC_GPIO_EMC_26_FLEXSPI2_A_DATA0 {
		pinmux = <0x401f807c 8 0x401f8730 1 0x401f826c>;
	};
	/omit-if-no-ref/ iomuxc_gpio_emc_27_flexspi2_a_data1: IOMUXC_GPIO_EMC_27_FLEXSPI2_A_DATA1 {
		pinmux = <0x401f8080 8 0x401f8734 1 0x401f8270>;
	};
	/omit-if-no-ref/ iomuxc_gpio_emc_28_flexspi2_a_data2: IOMUXC_GPIO_EMC_28_FLEXSPI2_A_DATA2 {
		pinmux = <0x401f8084 8 0x401f8738 1 0x401f8274>;
	};
	/omit-if-no-ref/ iomuxc_gpio_emc_29_flexspi2_a_data3: IOMUXC_GPIO_EMC_29_FLEXSPI2_A_DATA3 {
		pinmux = <0x401f8088 8 0x401f873c 1 0x401f8278>;
	};
	/omit-if-no-ref/ iomuxc_gpio_emc_33_enet2_ref_clk: IOMUXC_GPIO_EMC_33_ENET2_REF_CLK {
		pinmux = <0x401f8098 9 0x401f870c 0 0x401f8288>;
	};
	/omit-if-no-ref/ iomuxc_gpio_sd_b0_01_enet2_ref_clk: IOMUXC_GPIO_SD_B0_01_ENET2_REF_CLK {
		pinmux = <0x401f81c0 9 0x401f870c 1 0x401f83b0>;
	};
};
